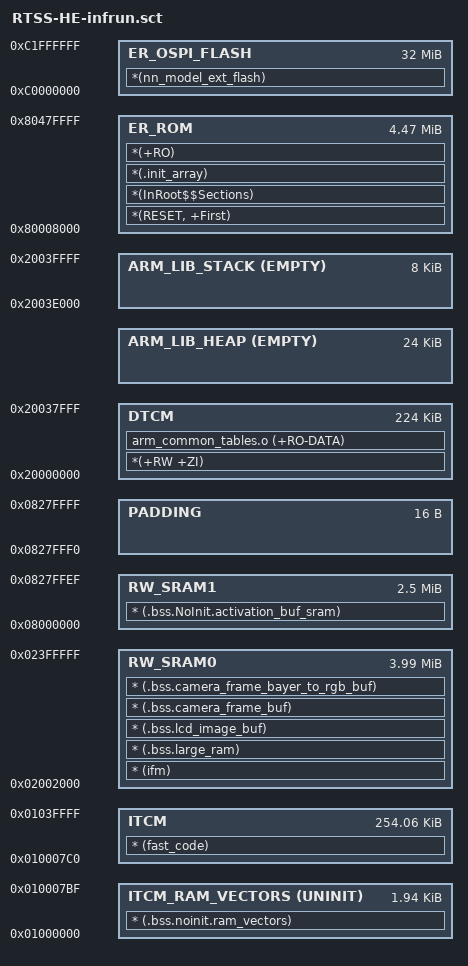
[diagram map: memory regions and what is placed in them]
#! armclang -E --target=arm-arm-none-eabi -mcpu=cortex-m55 -xc
; command above MUST be in first line (no comment above!)

;/* Copyright (C) 2022 Alif Semiconductor - All Rights Reserved.
; * Use, distribution and modification of this code is permitted under the
; * terms stated in the Alif Semiconductor Software License Agreement
; *
; * You should have received a copy of the Alif Semiconductor Software
; * License Agreement with this file. If not, please write to:
; * contact@alifsemi.com, or visit: https://alifsemi.com/license
; *
; */

/*On chip RAM Regions */
#define SRAM0_BASE                0x02000000
#define SRAM0_SIZE                0x00400000		/* 4M */
#define SRAM1_BASE                0x08000000
#define SRAM1_SIZE                0x00280000		/* 2.5M */
/* On Chip NVM */
#define MRAM_BASE                 0x80000000
#define MRAM_SIZE                 0x00580000		/* 5.5M */
/* External OSPI flash */
#define OSPI_FLASH_BASE           0xC0000000
#define OSPI_FLASH_SIZE           0x02000000        /* 32M */

/*--------------------- ITCM Configuration ----------------------------------*/
/* SRAM4 is mapped as ITCM */
#define ITCM_BASE                 0x01000000
#define ITCM_SIZE                 0x00040000        /* 256K */

/*--------------------- DTCM Configuration ---------------------------*/
/* SRAM5 is mapped as DTCM */
#define DTCM_BASE                 0x20000000
#define DTCM_SIZE                 0x00040000        /* 256K */

#define __VECTORS_SIZE  (496 * 4)
#define __STACK_SIZE    0x00002000
#define __HEAP_SIZE     0x00006000

;----------------------------------------------------------------------------
;   User Stack & Heap boundary definition
;----------------------------------------------------------------------------
#define __STACK_TOP     (DTCM_BASE + DTCM_SIZE)       /* starts at end of RAM */
#define __HEAP_BASE     (AlignExpr(+0, 8))            /* starts after RW_RAM section, 8 byte aligned */

;----------------------------------------------------------------------------
;  Scatter File Definitions definition
;----------------------------------------------------------------------------
#define __RO_BASE       (MRAM_BASE+0x8000)
#define __RO_SIZE       (0x80480000-__RO_BASE)

#define __RW_BASE       DTCM_BASE
#define __RW_SIZE      (DTCM_SIZE - __STACK_SIZE - __HEAP_SIZE)


LR_ROM __RO_BASE __RO_SIZE  {                       ; load region size_region
  ER_ROM __RO_BASE __RO_SIZE {                      ; load address = execution address
   ; MRAM has all read-only code and data except fast LVGL code and some maths tables
   ; This memory layout is a safe default for high-memory builds like the inference runner
   ; where the usual attempts to put inference code into ITCM dont fit
   *(RESET, +First)
   *(InRoot$$Sections)
   *(.init_array)
   *(+RO)
  }

  ITCM_RAM_VECTORS ITCM_BASE UNINIT ALIGN 2048 __VECTORS_SIZE {
      * (.bss.noinit.ram_vectors)
  }

  ITCM ITCM_BASE+__VECTORS_SIZE ITCM_SIZE-__VECTORS_SIZE {  ; --------------------------------
      ; ITCM has only fast LVGL and RAM vectors
      * (fast_code)
  }

  ;-----------------------------------------------------
  ; R/W region - remaining part of the DTCM region
  ; Other parts of this region used up by stack + heap.
  ;-----------------------------------------------------
  DTCM __RW_BASE __RW_SIZE  {  ; RW data in DTCM
      ; DTCM has CMSIS-DSP tables and all read-write data, except image and NPU buffers
      *(+RW +ZI)
      arm_common_tables.o (+RO-DATA)
  }

  ARM_LIB_HEAP  __HEAP_BASE EMPTY  __HEAP_SIZE  {  }
  ARM_LIB_STACK __STACK_TOP EMPTY -__STACK_SIZE {  }

; avoid first page, where default A32_APP stub is loaded
  RW_SRAM0 SRAM0_BASE+8192 SRAM0_SIZE-8192  {  ; 4MB ----------------------------
      * (ifm)                                ; Baked-in inputs
      * (.bss.large_ram)                     ; Large LVGL buffers
      * (.bss.lcd_image_buf)
      * (.bss.camera_frame_buf)              ; Camera Frame Buffer
      * (.bss.camera_frame_bayer_to_rgb_buf) ; (Optional) Camera Frame Buffer for Bayer to RGB Convertion.
  }

  RW_SRAM1 SRAM1_BASE SRAM1_SIZE-16  {  ; 2.5MB ----------------------------

      ; activation buffers a.k.a tensor arena when memory mode dedicated sram
      * (.bss.NoInit.activation_buf_sram)
  }

  PADDING SRAM1_BASE+SRAM1_SIZE-16 ALIGN 16 FILL 0 16  {  }
}

LR_OSPI_FLASH OSPI_FLASH_BASE OSPI_FLASH_SIZE  {
  ER_OSPI_FLASH OSPI_FLASH_BASE OSPI_FLASH_SIZE {
    *(nn_model_ext_flash)
  }
}
